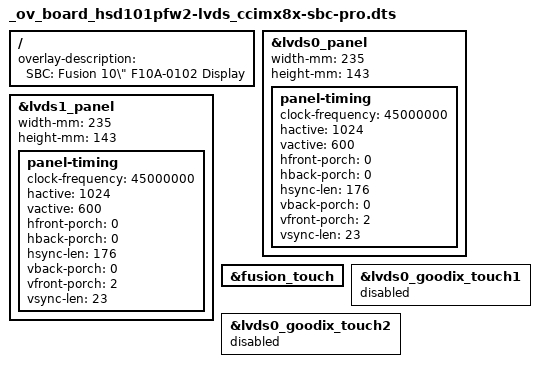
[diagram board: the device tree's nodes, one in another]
/*
 * Copyright 2020-2021 Digi International Inc.
 *
 * Permission to use, copy, modify, and/or distribute this software for any
 * purpose with or without fee is hereby granted, provided that the above
 * copyright notice and this permission notice appear in all copies.
 * THE SOFTWARE IS PROVIDED "AS IS" AND THE AUTHOR DISCLAIMS ALL WARRANTIES
 * WITH REGARD TO THIS SOFTWARE INCLUDING ALL IMPLIED WARRANTIES OF
 * MERCHANTABILITY AND FITNESS. IN NO EVENT SHALL THE AUTHOR BE LIABLE FOR
 * ANY SPECIAL, DIRECT, INDIRECT, OR CONSEQUENTIAL DAMAGES OR ANY DAMAGES
 * WHATSOEVER RESULTING FROM LOSS OF USE, DATA OR PROFITS, WHETHER IN AN
 * ACTION OF CONTRACT, NEGLIGENCE OR OTHER TORTIOUS ACTION, ARISING OUT OF
 * OR IN CONNECTION WITH THE USE OR PERFORMANCE OF THIS SOFTWARE.
 */

/dts-v1/;
/plugin/;

/ {
	fragment@0 {
		target-path = "/";
		__overlay__ {
			overlay-description = "SBC: Fusion 10\" F10A-0102 Display";
		};
	};

	/* Fusion 10" F10A-0102 on LVDS0 */
	fragment@1 {
		target = <&lvds0_panel>;
		__overlay__ {
			width-mm = <235>;
			height-mm = <143>;

			panel-timing {
				clock-frequency = <45000000>;
				hactive = <1024>;
				vactive = <600>;
				hfront-porch = <0>;
				hback-porch = <0>;
				hsync-len = <176>;
				vback-porch = <0>;
				vfront-porch = <2>;
				vsync-len = <23>;
			};
		};
	};

	/* Fusion 10" F10A-0102 on LVDS1 */
	fragment@2 {
		target = <&lvds1_panel>;
		__overlay__ {
			width-mm = <235>;
			height-mm = <143>;

			panel-timing {
				clock-frequency = <45000000>;
				hactive = <1024>;
				vactive = <600>;
				hfront-porch = <0>;
				hback-porch = <0>;
				hsync-len = <176>;
				vback-porch = <0>;
				vfront-porch = <2>;
				vsync-len = <23>;
			};
		};
	};

	/* Enable Fusion touch */
	fragment@3 {
		target = <&fusion_touch>;
		__overlay__ {
			status = "okay";
		};
	};

	/* Disable Goodix touch */
	fragment@4 {
		target = <&lvds0_goodix_touch1>;
		__overlay__ {
			status = "disabled";
		};
	};

	fragment@5 {
		target = <&lvds0_goodix_touch2>;
		__overlay__ {
			status = "disabled";
		};
	};
};
